# PIC18LF4685 register map
Vendor: Microchip
Architecture 18xxxx. Special function registers and configuration words.
Registers are 8-bit, read-write, no defined reset value unless marked. A register's access mark holds for its fields unless they carry their own. Addresses are absolute, and some are shared; only a register's first bit layout is shown; lines under a group give offsets from that group; [hi:lo] are bit positions; {n}, {i} and the like mark numbered series; 'fields as' and 'values as' point back to an identical list; <NAME> marks a mode.

## Further device data
pins=1: MCLR/Vpp/RE3; 2: RA0/AN0/CVref; 3: RA1/AN1; 4: RA2/AN2/Vref-; 5: RA3/AN3/Vref+; 6: RA4/T0CKI; 7: RA5/AN4/SS/HLVDIN; 8: RE0/RD/AN5; 9: RE1/WR/AN6/C1OUT; 10: RE2/CS/AN7/C2OUT; 11: Vdd; 12: Vss; 13: OSC1/CLKI/RA7; 14: OSC2/CLKO/RA6; 15: RC0/T1OSO/T13CKI; 16: RC1/T1OSI; 17: RC2/CCP1; 18: RC3/SCK/SCL; 19: RD0/PSP0/C1IN+; 20: RD1/PSP1/C1IN-; 21: RD2/PSP2/C2IN+; 22: RD3/PSP3/C2IN-; 23: RC4/SDI/SDA; 24: RC5/SDO; 25: RC6/TX/CK; 26: RC7/RX/DT; 27: RD4/PSP4/ECCP1/P1A; 28: RD5/PSP5/P1B; 29: RD6/PSP6/P1C; 30: RD7/PSP7/P1D; 31: Vss; 32: Vdd; 33: RB0/INT0/FLT0/AN10; 34: RB1/INT1/AN8; 35: RB2/INT2/CANTX; 36: RB3/CANRX; 37: RB4/KBI0/AN9; 38: RB5/KBI1/PGM; 39: RB6/KBI2/PGC; 40: RB7/KBI3/PGD

## CONFIG — Configuration words, addresses in ProgramSpace
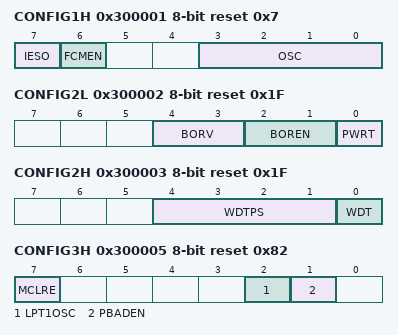
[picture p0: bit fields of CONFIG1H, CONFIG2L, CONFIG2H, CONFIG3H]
0x300001 CONFIG1H reset 0x7
  [7] IESO — Internal/External Oscillator Switchover bit
    1=ON (Oscillator Switchover mode enabled); 0=OFF (Oscillator Switchover mode disabled)
  [6] FCMEN — Fail-Safe Clock Monitor Enable bit
    1=ON (Fail-Safe Clock Monitor enabled); 0=OFF (Fail-Safe Clock Monitor disabled)
  [3:0] OSC — Oscillator Selection bits
    0b11xx=11XX External RC oscillator, CLKO function on RA6; 0b101x=101X External RC oscillator, CLKO function on RA6; 9=IRCIO7 (Internal oscillator block, CLKO function on RA6, port function on RA7); 8=IRCIO67 (Internal oscillator block, port function on RA6 and RA7); 7=RCIO (External RC oscillator, port function on RA6); 6=HSPLL (HS oscillator, PLL enabled (Clock Frequency = 4 x FOSC1)); 5=ECIO (EC oscillator, port function on RA6); 4=EC (EC oscillator, CLKO function on RA6); 3=RC (External RC oscillator, CLKO function on RA6); 2=HS (HS oscillator); 1=XT (XT oscillator); 0=LP (LP oscillator)
0x300002 CONFIG2L reset 0x1F
  [4:3] BORV — Brown-out Reset Voltage bits
    3=VBOR set to 2.1V; 2=VBOR set to 2.8V; 1=VBOR set to 4.3V; 0=VBOR set to 4.6V
  [2:1] BOREN — Brown-out Reset Enable bits
    3=BOHW (Brown-out Reset enabled in hardware only (SBOREN is disabled)); 2=BOACTIVE (Brown-out Reset enabled in hardware only and disabled in Sleep mode (SBOREN is disabled)); 1=SBORENCTRL (Brown-out Reset enabled and controlled by software (SBOREN is enabled)); 0=OFF (Brown-out Reset disabled in hardware and software)
  [0] PWRT — Power-up Timer Enable bit
    1=OFF (PWRT disabled); 0=ON (PWRT enabled)
0x300003 CONFIG2H reset 0x1F
  [4:1] WDTPS — Watchdog Timer Postscale Select bits
    15=1:32768; 14=1:16384; 13=1:8192; 12=1:4096; 11=1:2048; 10=1:1024; 9=1:512; 8=1:256; 7=1:128; 6=1:64; 5=1:32; 4=1:16; 3=1:8; 2=1:4; 1=1:2; 0=1:1
  [0] WDT — Watchdog Timer Enable bit
    1=ON (WDT enabled); 0=OFF (WDT disabled (control is placed on the SWDTEN bit))
0x300005 CONFIG3H reset 0x82
  [7] MCLRE — MCLR Pin Enable bit
    1=ON (MCLR pin enabled; RE3 input pin disabled); 0=OFF (RE3 input pin enabled; MCLR disabled)
  [2] LPT1OSC — Low-Power Timer 1 Oscillator Enable bit
    1=ON (Timer1 configured for low-power operation); 0=OFF (Timer1 configured for higher power operation)
  [1] PBADEN — PORTB A/D Enable bit
    1=ON (PORTB<4:0> pins are configured as analog input channels on Reset); 0=OFF (PORTB<4:0> pins are configured as digital I/O on Reset)
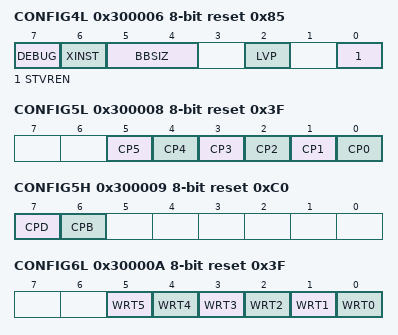
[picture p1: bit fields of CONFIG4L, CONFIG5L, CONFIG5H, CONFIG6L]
0x300006 CONFIG4L reset 0x85
  [7] DEBUG — Background Debugger Enable bit
    1=OFF (Background debugger disabled, RB6 and RB7 configured as general purpose I/O pins); 0=ON (Background debugger enabled, RB6 and RB7 are dedicated to In-Circuit Debug)
  [6] XINST — Extended Instruction Set Enable bit
    1=ON (Instruction set extension and Indexed Addressing mode enabled); 0=OFF (Instruction set extension and Indexed Addressing mode disabled (Legacy mode))
  [5:4] BBSIZ — Boot Block Size Select bits
    0b1x=4K words (8K bytes) Boot Block; 1=2K words (4K bytes) Boot Block; 0=1K words (2K bytes) Boot Block
  [2] LVP — Single-Supply ICSP Enable bit
    1=ON (Single-Supply ICSP enabled); 0=OFF (Single-Supply ICSP disabled)
  [0] STVREN — Stack Full/Underflow Reset Enable bit
    1=ON (Stack full/underflow will cause Reset); 0=OFF (Stack full/underflow will not cause Reset)
0x300008 CONFIG5L reset 0x3F
  [5] CP5 — Code Protection bit
    1=OFF (Block 5 (014000-017FFFh) not code-protected); 0=ON (Block 5 (014000-017FFFh) code-protected)
  [4] CP4 — Code Protection bit
    1=OFF (Block 4 (010000-013FFFh) not code-protected); 0=ON (Block 4 (010000-013FFFh) code-protected)
  [3] CP3 — Code Protection bit
    1=OFF (Block 3 (00C000-00FFFFh) not code-protected); 0=ON (Block 3 (00C000-00FFFFh) code-protected)
  [2] CP2 — Code Protection bit
    1=OFF (Block 2 (008000-00BFFFh) not code-protected); 0=ON (Block 2 (008000-00BFFFh) code-protected)
  [1] CP1 — Code Protection bit
    1=OFF (Block 1 (004000-007FFFh) not code-protected); 0=ON (Block 1 (004000-007FFFh) code-protected)
  [0] CP0 — Code Protection bit
    1=OFF (Block 0 (000800-003FFFh) not code-protected); 0=ON (Block 0 (000800-003FFFh) code-protected)
0x300009 CONFIG5H reset 0xC0
  [7] CPD — Data EEPROM Code Protection bit
    1=OFF (Data EEPROM not code-protected); 0=ON (Data EEPROM code-protected)
  [6] CPB — Boot Block Code Protection bit
    1=OFF (Boot block (000000-0007FFh) not code-protected); 0=ON (Boot block (000000-0007FFh) code-protected)
0x30000A CONFIG6L reset 0x3F
  [5] WRT5 — Write Protection bit
    1=OFF (Block 5 (014000-017FFFh) not write-protected); 0=ON (Block 5 (014000-017FFFh) write-protected)
  [4] WRT4 — Write Protection bit
    1=OFF (Block 4 (010000-013FFFh) not write-protected); 0=ON (Block 4 (010000-013FFFh) write-protected)
  [3] WRT3 — Write Protection bit
    1=OFF (Block 3 (00C000-00FFFFh) not write-protected); 0=ON (Block 3 (00C000-00FFFFh) write-protected)
  [2] WRT2 — Write Protection bit
    1=OFF (Block 2 (008000-00BFFFh) not write-protected); 0=ON (Block 2 (008000-00BFFFh) write-protected)
  [1] WRT1 — Write Protection bit
    1=OFF (Block 1 (004000-007FFFh) not write-protected); 0=ON (Block 1 (004000-007FFFh) write-protected)
  [0] WRT0 — Write Protection bit
    1=OFF (Block 0 (000800-003FFFh) not write-protected); 0=ON (Block 0 (000800-003FFFh) write-protected)
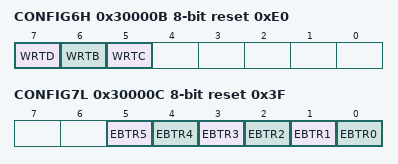
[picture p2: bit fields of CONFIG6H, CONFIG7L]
0x30000B CONFIG6H reset 0xE0
  [7] WRTD — Data EEPROM Write Protection bit
    1=OFF (Data EEPROM not write-protected); 0=ON (Data EEPROM write-protected)
  [6] WRTB — Boot Block Write Protection bit
    1=OFF (Boot block (000000-0007FFh) not write-protected); 0=ON (Boot block (000000-0007FFh) write-protected)
  [5] WRTC — Configuration Register Write Protection bit
    1=OFF (Configuration registers (300000-3000FFh) not write-protected); 0=ON (Configuration registers (300000-3000FFh) write-protected)
0x30000C CONFIG7L reset 0x3F
  [5] EBTR5 — Table Read Protection bit
    1=OFF (Block 5 (014000-017FFFh) not protected from table reads executed in other blocks); 0=ON (Block 5 (014000-017FFFh) protected from table reads executed in other blocks)
  [4] EBTR4 — Table Read Protection bit
    1=OFF (Block 4 (010000-013FFFh) not protected from table reads executed in other blocks); 0=ON (Block 4 (010000-013FFFh) protected from table reads executed in other blocks)
  [3] EBTR3 — Table Read Protection bit
    1=OFF (Block 3 (00C000-00FFFFh) not protected from table reads executed in other blocks); 0=ON (Block 3 (00C000-00FFFFh) protected from table reads executed in other blocks)
  [2] EBTR2 — Table Read Protection bit
    1=OFF (Block 2 (008000-00BFFFh) not protected from table reads executed in other blocks); 0=ON (Block 2 (008000-00BFFFh) protected from table reads executed in other blocks)
  [1] EBTR1 — Table Read Protection bit
    1=OFF (Block 1 (004000-007FFFh) not protected from table reads executed in other blocks); 0=ON (Block 1 (004000-007FFFh) protected from table reads executed in other blocks)
  [0] EBTR0 — Table Read Protection bit
    1=OFF (Block 0 (000800-003FFFh) not protected from table reads executed in other blocks); 0=ON (Block 0 (000800-003FFFh) protected from table reads executed in other blocks)
0x30000D CONFIG7H reset 0x40
  [6] EBTRB — Boot Block Table Read Protection bit
    1=OFF (Boot block (000000-0007FFh) not protected from table reads executed in other blocks); 0=ON (Boot block (000000-0007FFh) protected from table reads executed in other blocks)
